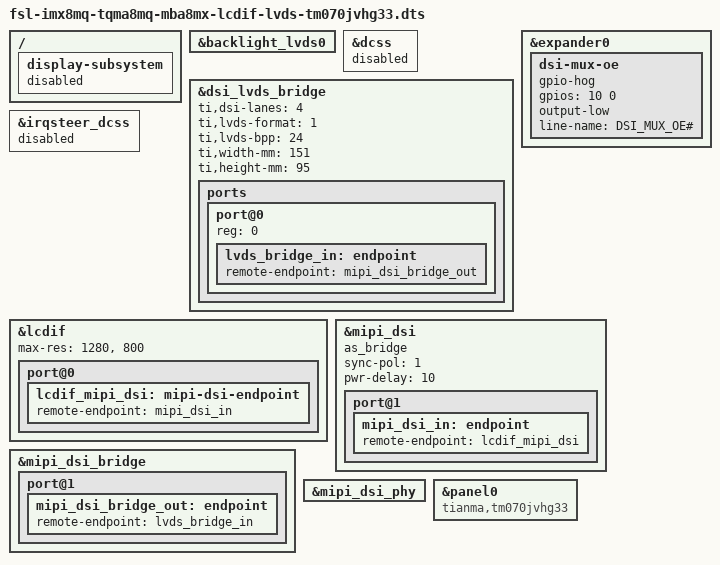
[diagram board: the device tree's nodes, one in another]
/*
 * Copyright 2019 TQ Systems GmbH
 *
 * This program is free software; you can redistribute it and/or
 * modify it under the terms of the GNU General Public License
 * as published by the Free Software Foundation; either version 2
 * of the License, or (at your option) any later version.
 *
 * This program is distributed in the hope that it will be useful,
 * but WITHOUT ANY WARRANTY; without even the implied warranty of
 * MERCHANTABILITY or FITNESS FOR A PARTICULAR PURPOSE.  See the
 * GNU General Public License for more details.
 */

#include "fsl-imx8mq-tqma8mq-mba8mx.dts"

/ {
	display-subsystem {
		status = "disabled";
	};
};

&backlight_lvds0 {
	status = "okay";
};

&dcss {
	status = "disabled";
};

&dsi_lvds_bridge {
	ti,dsi-lanes = <4>;
	ti,lvds-format = <1>;
	ti,lvds-bpp = <24>;
	ti,width-mm = <151>;
	ti,height-mm = <95>;
	status = "okay";

	ports {
		port@0 {
			reg = <0>;

			lvds_bridge_in: endpoint {
				remote-endpoint = <&mipi_dsi_bridge_out>;
			};
		};
	};
};

&expander0 {
	dsi-mux-oe {
		gpio-hog;
		gpios = <10 0>;
		output-low;
		line-name = "DSI_MUX_OE#";
	};
};

&irqsteer_dcss {
	status = "disabled";
};

&lcdif {
	status = "okay";
	max-res = <1280>, <800>;

	port@0 {
		lcdif_mipi_dsi: mipi-dsi-endpoint {
			remote-endpoint = <&mipi_dsi_in>;
		};
	};
};

&mipi_dsi {
	status = "okay";
	/* use lcdif as input */
	as_bridge;
	sync-pol = <1>;
	pwr-delay = <10>;

	port@1 {
		mipi_dsi_in: endpoint {
			remote-endpoint = <&lcdif_mipi_dsi>;
		};
	};
};

&mipi_dsi_bridge {
	status = "okay";

	port@1 {
		mipi_dsi_bridge_out: endpoint {
			remote-endpoint = <&lvds_bridge_in>;
		};
	};
};

&mipi_dsi_phy {
	status = "okay";
};

&panel0 {
	compatible = "tianma,tm070jvhg33";
	status = "okay";
};
